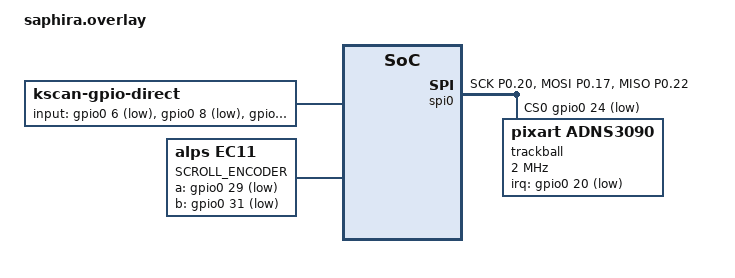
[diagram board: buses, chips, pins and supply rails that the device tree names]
#include <dt-bindings/zmk/matrix_transform.h>

/ {
    chosen {
        zmk,kscan = &kscan0;
    }

    kscan0: kscan {
        compatible = "zmk,kscan-gpio-direct";
        label = "KSCAN";
        input-gpios
            = <&gpio0 6  (GPIO_ACTIVE_LOW | GPIO_PULL_UP)> // Sol Tık (D4 / P0.06)
            , <&gpio0 8  (GPIO_ACTIVE_LOW | GPIO_PULL_UP)> // Sağ Tık (D5 / P0.08)
            , <&gpio1 0  (GPIO_ACTIVE_LOW | GPIO_PULL_UP)> // Orta Tık (D6 / P1.00)
            , <&gpio1 6  (GPIO_ACTIVE_LOW | GPIO_PULL_UP)> // Yan Tuş 1 (D7 / P1.06)
            , <&gpio0 11 (GPIO_ACTIVE_LOW | GPIO_PULL_UP)> // Yan Tuş 2 (D2 / P0.11)
            ;
    };

    encoder: encoder {
        compatible = "alps,ec11";
        label = "SCROLL_ENCODER";
        a-gpios = <&gpio0 29 (GPIO_ACTIVE_LOW | GPIO_PULL_UP)>; // EN1 (P0.29)
        b-gpios = <&gpio0 31 (GPIO_ACTIVE_LOW | GPIO_PULL_UP)>; // EN2 (P0.31)
        steps = <24>;
    };

    sensors {
        compatible = "zmk,keymap-sensors";
        sensors = <&encoder>;
        triggers-per-rotation = <24>;
    };
};

&pinctrl {
    spi0_default: spi0_default {
        group1 {
            psels = <NRF_PSEL(SPIM_SCK, 0, 20)>,  // S0 (SCK - P0.20)
                    <NRF_PSEL(SPIM_MOSI, 0, 17)>, // R1 (SDIO / MOSI - P0.17)
                    <NRF_PSEL(SPIM_MISO, 0, 22)>; // R0 (SDIO / MISO - P0.22)
        };
    };
};

&spi0 {
    status = "okay";
    pinctrl-0 = <&spi0_default>;
    pinctrl-names = "default";
    cs-gpios = <&gpio0 24 GPIO_ACTIVE_LOW>; // R2 (NCS - P0.24)

    trackball: trackball@0 {
        status = "okay";
        compatible = "pixart,adns3090";
        reg = <0>;
        spi-max-frequency = <2000000>;
        irq-gpios = <&gpio0 20 (GPIO_ACTIVE_LOW | GPIO_PULL_UP)>;
    };
};
